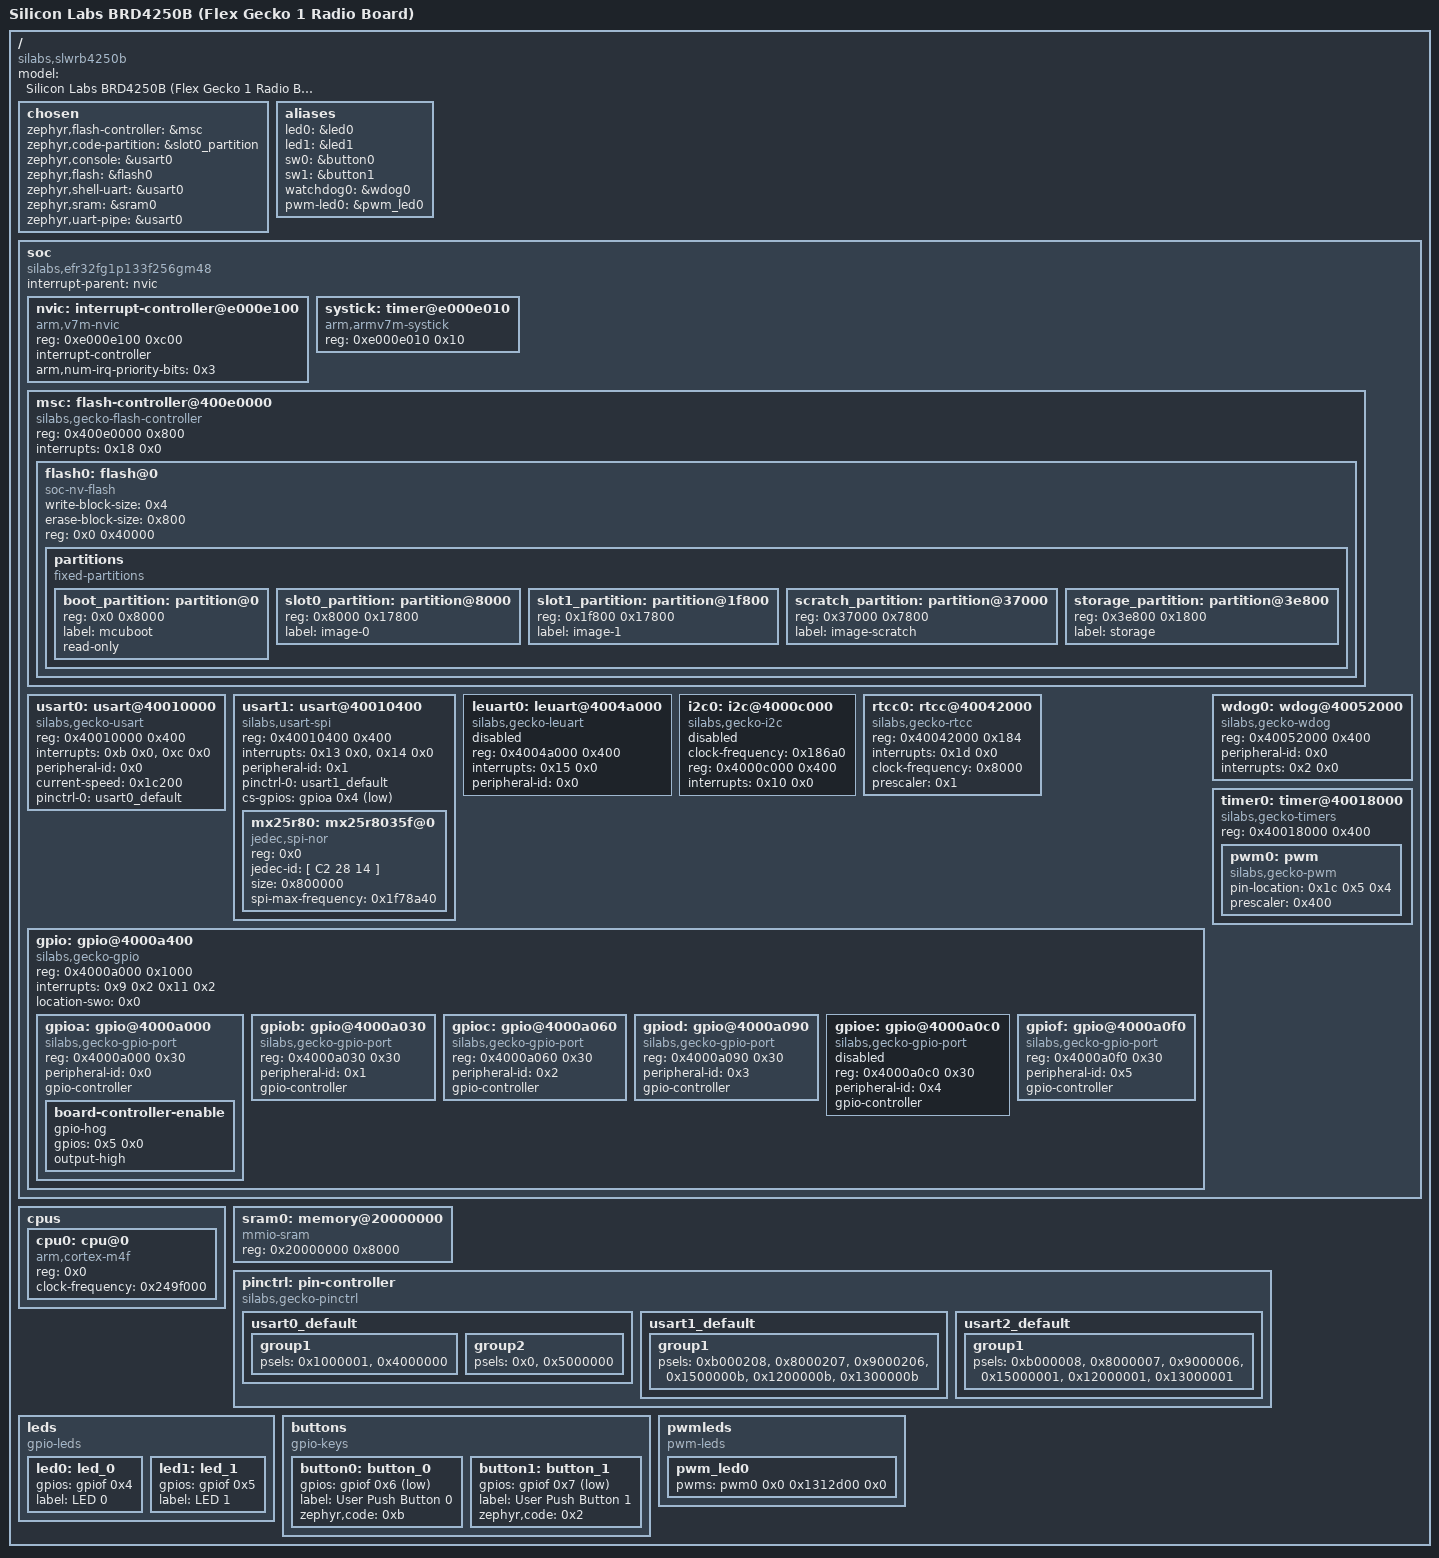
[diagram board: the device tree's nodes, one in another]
/dts-v1/;

/* node '/' defined in zephyr/dts/common/skeleton.dtsi:9 */
/ {
	#address-cells = < 0x1 >;                                   /* in zephyr/dts/common/skeleton.dtsi:10 */
	#size-cells = < 0x1 >;                                      /* in zephyr/dts/common/skeleton.dtsi:11 */
	model = "Silicon Labs BRD4250B (Flex Gecko 1 Radio Board)"; /* in zephyr/boards/silabs/radio_boards/slwrb4250b/slwrb4250b.dts:13 */
	compatible = "silabs,slwrb4250b",
	             "silabs,efr32fg1p";                            /* in zephyr/boards/silabs/radio_boards/slwrb4250b/slwrb4250b.dts:14 */

	/* node '/chosen' defined in zephyr/dts/common/skeleton.dtsi:13 */
	chosen {
		zephyr,flash-controller = &msc;           /* in zephyr/dts/arm/silabs/xg1/xg1.dtsi:10 */
		zephyr,code-partition = &slot0_partition; /* in zephyr/boards/silabs/radio_boards/common/efr32-series1-common.dtsi:12 */
		zephyr,console = &usart0;                 /* in zephyr/boards/silabs/radio_boards/common/efr32-series1-common.dtsi:13 */
		zephyr,flash = &flash0;                   /* in zephyr/boards/silabs/radio_boards/common/efr32-series1-common.dtsi:14 */
		zephyr,shell-uart = &usart0;              /* in zephyr/boards/silabs/radio_boards/common/efr32-series1-common.dtsi:15 */
		zephyr,sram = &sram0;                     /* in zephyr/boards/silabs/radio_boards/common/efr32-series1-common.dtsi:16 */
		zephyr,uart-pipe = &usart0;               /* in zephyr/boards/silabs/radio_boards/common/efr32-series1-common.dtsi:17 */
	};

	/* node '/aliases' defined in zephyr/dts/common/skeleton.dtsi:15 */
	aliases {
		led0 = &led0;         /* in zephyr/boards/silabs/radio_boards/common/efr32-series1-common.dtsi:22 */
		led1 = &led1;         /* in zephyr/boards/silabs/radio_boards/common/efr32-series1-common.dtsi:23 */
		sw0 = &button0;       /* in zephyr/boards/silabs/radio_boards/common/efr32-series1-common.dtsi:24 */
		sw1 = &button1;       /* in zephyr/boards/silabs/radio_boards/common/efr32-series1-common.dtsi:25 */
		watchdog0 = &wdog0;   /* in zephyr/boards/silabs/radio_boards/common/efr32-series1-common.dtsi:26 */
		pwm-led0 = &pwm_led0; /* in zephyr/boards/silabs/radio_boards/slwrb4250b/slwrb4250b.dts:17 */
	};

	/* node '/soc' defined in zephyr/dts/arm/armv7-m.dtsi:6 */
	soc {
		#address-cells = < 0x1 >;                   /* in zephyr/dts/arm/armv7-m.dtsi:7 */
		#size-cells = < 0x1 >;                      /* in zephyr/dts/arm/armv7-m.dtsi:8 */
		interrupt-parent = < &nvic >;               /* in zephyr/dts/arm/armv7-m.dtsi:10 */
		ranges;                                     /* in zephyr/dts/arm/armv7-m.dtsi:11 */
		compatible = "silabs,efr32fg1p133f256gm48",
		             "silabs,efr32fg1p",
		             "silabs,efr32",
		             "simple-bus";                  /* in zephyr/dts/arm/silabs/xg1/efr32fg1p133f256gm48.dtsi:12 */

		/* node '/soc/interrupt-controller@e000e100' defined in zephyr/dts/arm/armv7-m.dtsi:13 */
		nvic: interrupt-controller@e000e100 {
			#address-cells = < 0x1 >;            /* in zephyr/dts/arm/armv7-m.dtsi:14 */
			compatible = "arm,v7m-nvic";         /* in zephyr/dts/arm/armv7-m.dtsi:15 */
			reg = < 0xe000e100 0xc00 >;          /* in zephyr/dts/arm/armv7-m.dtsi:16 */
			interrupt-controller;                /* in zephyr/dts/arm/armv7-m.dtsi:17 */
			#interrupt-cells = < 0x2 >;          /* in zephyr/dts/arm/armv7-m.dtsi:18 */
			arm,num-irq-priority-bits = < 0x3 >; /* in zephyr/dts/arm/silabs/xg1/xg1.dtsi:184 */
			phandle = < 0x1 >;                   /* in zephyr/dts/arm/armv7-m.dtsi:10 */
		};

		/* node '/soc/timer@e000e010' defined in zephyr/dts/arm/armv7-m.dtsi:21 */
		systick: timer@e000e010 {
			compatible = "arm,armv7m-systick"; /* in zephyr/dts/arm/armv7-m.dtsi:22 */
			reg = < 0xe000e010 0x10 >;         /* in zephyr/dts/arm/armv7-m.dtsi:23 */
		};

		/* node '/soc/flash-controller@400e0000' defined in zephyr/dts/arm/silabs/xg1/xg1.dtsi:28 */
		msc: flash-controller@400e0000 {
			compatible = "silabs,gecko-flash-controller"; /* in zephyr/dts/arm/silabs/xg1/xg1.dtsi:29 */
			reg = < 0x400e0000 0x800 >;                   /* in zephyr/dts/arm/silabs/xg1/xg1.dtsi:30 */
			interrupts = < 0x18 0x0 >;                    /* in zephyr/dts/arm/silabs/xg1/xg1.dtsi:31 */
			#address-cells = < 0x1 >;                     /* in zephyr/dts/arm/silabs/xg1/xg1.dtsi:33 */
			#size-cells = < 0x1 >;                        /* in zephyr/dts/arm/silabs/xg1/xg1.dtsi:34 */

			/* node '/soc/flash-controller@400e0000/flash@0' defined in zephyr/dts/arm/silabs/xg1/xg1.dtsi:36 */
			flash0: flash@0 {
				compatible = "soc-nv-flash";  /* in zephyr/dts/arm/silabs/xg1/xg1.dtsi:37 */
				write-block-size = < 0x4 >;   /* in zephyr/dts/arm/silabs/xg1/xg1.dtsi:38 */
				erase-block-size = < 0x800 >; /* in zephyr/dts/arm/silabs/xg1/xg1.dtsi:39 */
				reg = < 0x0 0x40000 >;        /* in zephyr/dts/arm/silabs/xg1/efr32fg1p133f256gm48.dtsi:17 */

				/* node '/soc/flash-controller@400e0000/flash@0/partitions' defined in zephyr/boards/silabs/radio_boards/slwrb4250b/slwrb4250b.dts:44 */
				partitions {
					compatible = "fixed-partitions"; /* in zephyr/boards/silabs/radio_boards/slwrb4250b/slwrb4250b.dts:45 */
					#address-cells = < 0x1 >;        /* in zephyr/boards/silabs/radio_boards/slwrb4250b/slwrb4250b.dts:46 */
					#size-cells = < 0x1 >;           /* in zephyr/boards/silabs/radio_boards/slwrb4250b/slwrb4250b.dts:47 */

					/* node '/soc/flash-controller@400e0000/flash@0/partitions/partition@0' defined in zephyr/boards/silabs/radio_boards/slwrb4250b/slwrb4250b.dts:50 */
					boot_partition: partition@0 {
						reg = < 0x0 0x8000 >; /* in zephyr/boards/silabs/radio_boards/slwrb4250b/slwrb4250b.dts:51 */
						label = "mcuboot";    /* in zephyr/boards/silabs/radio_boards/slwrb4250b/slwrb4250b.dts:52 */
						read-only;            /* in zephyr/boards/silabs/radio_boards/slwrb4250b/slwrb4250b.dts:53 */
					};

					/* node '/soc/flash-controller@400e0000/flash@0/partitions/partition@8000' defined in zephyr/boards/silabs/radio_boards/slwrb4250b/slwrb4250b.dts:57 */
					slot0_partition: partition@8000 {
						reg = < 0x8000 0x17800 >; /* in zephyr/boards/silabs/radio_boards/slwrb4250b/slwrb4250b.dts:58 */
						label = "image-0";        /* in zephyr/boards/silabs/radio_boards/slwrb4250b/slwrb4250b.dts:59 */
					};

					/* node '/soc/flash-controller@400e0000/flash@0/partitions/partition@1f800' defined in zephyr/boards/silabs/radio_boards/slwrb4250b/slwrb4250b.dts:63 */
					slot1_partition: partition@1f800 {
						reg = < 0x1f800 0x17800 >; /* in zephyr/boards/silabs/radio_boards/slwrb4250b/slwrb4250b.dts:64 */
						label = "image-1";         /* in zephyr/boards/silabs/radio_boards/slwrb4250b/slwrb4250b.dts:65 */
					};

					/* node '/soc/flash-controller@400e0000/flash@0/partitions/partition@37000' defined in zephyr/boards/silabs/radio_boards/slwrb4250b/slwrb4250b.dts:69 */
					scratch_partition: partition@37000 {
						reg = < 0x37000 0x7800 >; /* in zephyr/boards/silabs/radio_boards/slwrb4250b/slwrb4250b.dts:70 */
						label = "image-scratch";  /* in zephyr/boards/silabs/radio_boards/slwrb4250b/slwrb4250b.dts:71 */
					};

					/* node '/soc/flash-controller@400e0000/flash@0/partitions/partition@3e800' defined in zephyr/boards/silabs/radio_boards/slwrb4250b/slwrb4250b.dts:75 */
					storage_partition: partition@3e800 {
						reg = < 0x3e800 0x1800 >; /* in zephyr/boards/silabs/radio_boards/slwrb4250b/slwrb4250b.dts:76 */
						label = "storage";        /* in zephyr/boards/silabs/radio_boards/slwrb4250b/slwrb4250b.dts:77 */
					};
				};
			};
		};

		/* node '/soc/usart@40010000' defined in zephyr/dts/arm/silabs/xg1/xg1.dtsi:43 */
		usart0: usart@40010000 {
			compatible = "silabs,gecko-usart"; /* in zephyr/dts/arm/silabs/xg1/xg1.dtsi:44 */
			reg = < 0x40010000 0x400 >;        /* in zephyr/dts/arm/silabs/xg1/xg1.dtsi:45 */
			interrupts = < 0xb 0x0 >,
			             < 0xc 0x0 >;          /* in zephyr/dts/arm/silabs/xg1/xg1.dtsi:46 */
			interrupt-names = "rx",
			                  "tx";            /* in zephyr/dts/arm/silabs/xg1/xg1.dtsi:47 */
			peripheral-id = < 0x0 >;           /* in zephyr/dts/arm/silabs/xg1/xg1.dtsi:48 */
			current-speed = < 0x1c200 >;       /* in zephyr/boards/silabs/radio_boards/slwrb4250b/slwrb4250b.dts:83 */
			pinctrl-0 = < &usart0_default >;   /* in zephyr/boards/silabs/radio_boards/slwrb4250b/slwrb4250b.dts:84 */
			pinctrl-names = "default";         /* in zephyr/boards/silabs/radio_boards/slwrb4250b/slwrb4250b.dts:85 */
			status = "okay";                   /* in zephyr/boards/silabs/radio_boards/slwrb4250b/slwrb4250b.dts:86 */
		};

		/* node '/soc/usart@40010400' defined in zephyr/dts/arm/silabs/xg1/xg1.dtsi:52 */
		usart1: usart@40010400 {
			reg = < 0x40010400 0x400 >;      /* in zephyr/dts/arm/silabs/xg1/xg1.dtsi:54 */
			interrupts = < 0x13 0x0 >,
			             < 0x14 0x0 >;       /* in zephyr/dts/arm/silabs/xg1/xg1.dtsi:55 */
			interrupt-names = "rx",
			                  "tx";          /* in zephyr/dts/arm/silabs/xg1/xg1.dtsi:56 */
			peripheral-id = < 0x1 >;         /* in zephyr/dts/arm/silabs/xg1/xg1.dtsi:57 */
			compatible = "silabs,usart-spi"; /* in zephyr/boards/silabs/radio_boards/common/efr32-series1-common.dtsi:70 */
			#address-cells = < 0x1 >;        /* in zephyr/boards/silabs/radio_boards/common/efr32-series1-common.dtsi:72 */
			#size-cells = < 0x0 >;           /* in zephyr/boards/silabs/radio_boards/common/efr32-series1-common.dtsi:73 */
			pinctrl-0 = < &usart1_default >; /* in zephyr/boards/silabs/radio_boards/common/efr32-series1-common.dtsi:75 */
			pinctrl-names = "default";       /* in zephyr/boards/silabs/radio_boards/common/efr32-series1-common.dtsi:76 */
			cs-gpios = < &gpioa 0x4 0x1 >;   /* in zephyr/boards/silabs/radio_boards/common/efr32-series1-common.dtsi:78 */
			status = "okay";                 /* in zephyr/boards/silabs/radio_boards/common/efr32-series1-common.dtsi:80 */

			/* node '/soc/usart@40010400/mx25r8035f@0' defined in zephyr/boards/silabs/radio_boards/common/efr32-series1-common.dtsi:82 */
			mx25r80: mx25r8035f@0 {
				compatible = "jedec,spi-nor";      /* in zephyr/boards/silabs/radio_boards/common/efr32-series1-common.dtsi:83 */
				reg = < 0x0 >;                     /* in zephyr/boards/silabs/radio_boards/common/efr32-series1-common.dtsi:84 */
				jedec-id = [ C2 28 14 ];           /* in zephyr/boards/silabs/radio_boards/common/efr32-series1-common.dtsi:85 */
				size = < 0x800000 >;               /* in zephyr/boards/silabs/radio_boards/common/efr32-series1-common.dtsi:86 */
				spi-max-frequency = < 0x1f78a40 >; /* in zephyr/boards/silabs/radio_boards/common/efr32-series1-common.dtsi:87 */
			};
		};

		/* node '/soc/leuart@4004a000' defined in zephyr/dts/arm/silabs/xg1/xg1.dtsi:61 */
		leuart0: leuart@4004a000 {
			compatible = "silabs,gecko-leuart"; /* in zephyr/dts/arm/silabs/xg1/xg1.dtsi:62 */
			reg = < 0x4004a000 0x400 >;         /* in zephyr/dts/arm/silabs/xg1/xg1.dtsi:63 */
			interrupts = < 0x15 0x0 >;          /* in zephyr/dts/arm/silabs/xg1/xg1.dtsi:64 */
			peripheral-id = < 0x0 >;            /* in zephyr/dts/arm/silabs/xg1/xg1.dtsi:65 */
			status = "disabled";                /* in zephyr/dts/arm/silabs/xg1/xg1.dtsi:66 */
		};

		/* node '/soc/i2c@4000c000' defined in zephyr/dts/arm/silabs/xg1/xg1.dtsi:69 */
		i2c0: i2c@4000c000 {
			compatible = "silabs,gecko-i2c"; /* in zephyr/dts/arm/silabs/xg1/xg1.dtsi:70 */
			clock-frequency = < 0x186a0 >;   /* in zephyr/dts/arm/silabs/xg1/xg1.dtsi:71 */
			#address-cells = < 0x1 >;        /* in zephyr/dts/arm/silabs/xg1/xg1.dtsi:72 */
			#size-cells = < 0x0 >;           /* in zephyr/dts/arm/silabs/xg1/xg1.dtsi:73 */
			reg = < 0x4000c000 0x400 >;      /* in zephyr/dts/arm/silabs/xg1/xg1.dtsi:74 */
			interrupts = < 0x10 0x0 >;       /* in zephyr/dts/arm/silabs/xg1/xg1.dtsi:75 */
			status = "disabled";             /* in zephyr/dts/arm/silabs/xg1/xg1.dtsi:76 */
		};

		/* node '/soc/rtcc@40042000' defined in zephyr/dts/arm/silabs/xg1/xg1.dtsi:79 */
		rtcc0: rtcc@40042000 {
			compatible = "silabs,gecko-rtcc"; /* in zephyr/dts/arm/silabs/xg1/xg1.dtsi:80 */
			reg = < 0x40042000 0x184 >;       /* in zephyr/dts/arm/silabs/xg1/xg1.dtsi:81 */
			interrupts = < 0x1d 0x0 >;        /* in zephyr/dts/arm/silabs/xg1/xg1.dtsi:82 */
			clock-frequency = < 0x8000 >;     /* in zephyr/dts/arm/silabs/xg1/xg1.dtsi:83 */
			prescaler = < 0x1 >;              /* in zephyr/boards/silabs/radio_boards/common/efr32-series1-common.dtsi:92 */
			status = "okay";                  /* in zephyr/boards/silabs/radio_boards/common/efr32-series1-common.dtsi:93 */
		};

		/* node '/soc/gpio@4000a400' defined in zephyr/dts/arm/silabs/xg1/xg1.dtsi:88 */
		gpio: gpio@4000a400 {
			compatible = "silabs,gecko-gpio";  /* in zephyr/dts/arm/silabs/xg1/xg1.dtsi:89 */
			reg = < 0x4000a000 0x1000 >;       /* in zephyr/dts/arm/silabs/xg1/xg1.dtsi:90 */
			interrupts = < 0x9 0x2 0x11 0x2 >; /* in zephyr/dts/arm/silabs/xg1/xg1.dtsi:91 */
			interrupt-names = "GPIO_EVEN",
			                  "GPIO_ODD";      /* in zephyr/dts/arm/silabs/xg1/xg1.dtsi:92 */
			ranges;                            /* in zephyr/dts/arm/silabs/xg1/xg1.dtsi:94 */
			#address-cells = < 0x1 >;          /* in zephyr/dts/arm/silabs/xg1/xg1.dtsi:95 */
			#size-cells = < 0x1 >;             /* in zephyr/dts/arm/silabs/xg1/xg1.dtsi:96 */
			location-swo = < 0x0 >;            /* in zephyr/boards/silabs/radio_boards/common/efr32-series1-common.dtsi:97 */
			status = "okay";                   /* in zephyr/boards/silabs/radio_boards/common/efr32-series1-common.dtsi:98 */

			/* node '/soc/gpio@4000a400/gpio@4000a000' defined in zephyr/dts/arm/silabs/xg1/xg1.dtsi:98 */
			gpioa: gpio@4000a000 {
				compatible = "silabs,gecko-gpio-port"; /* in zephyr/dts/arm/silabs/xg1/xg1.dtsi:99 */
				reg = < 0x4000a000 0x30 >;             /* in zephyr/dts/arm/silabs/xg1/xg1.dtsi:100 */
				peripheral-id = < 0x0 >;               /* in zephyr/dts/arm/silabs/xg1/xg1.dtsi:101 */
				gpio-controller;                       /* in zephyr/dts/arm/silabs/xg1/xg1.dtsi:102 */
				#gpio-cells = < 0x2 >;                 /* in zephyr/dts/arm/silabs/xg1/xg1.dtsi:103 */
				status = "okay";                       /* in zephyr/boards/silabs/radio_boards/common/efr32-series1-common.dtsi:102 */
				phandle = < 0x4 >;                     /* in zephyr/boards/silabs/radio_boards/common/efr32-series1-common.dtsi:78 */

				/* node '/soc/gpio@4000a400/gpio@4000a000/board-controller-enable' defined in zephyr/boards/silabs/radio_boards/common/efr32-series1-common.dtsi:104 */
				board-controller-enable {
					gpio-hog;            /* in zephyr/boards/silabs/radio_boards/common/efr32-series1-common.dtsi:105 */
					gpios = < 0x5 0x0 >; /* in zephyr/boards/silabs/radio_boards/common/efr32-series1-common.dtsi:106 */
					output-high;         /* in zephyr/boards/silabs/radio_boards/common/efr32-series1-common.dtsi:107 */
				};
			};

			/* node '/soc/gpio@4000a400/gpio@4000a030' defined in zephyr/dts/arm/silabs/xg1/xg1.dtsi:107 */
			gpiob: gpio@4000a030 {
				compatible = "silabs,gecko-gpio-port"; /* in zephyr/dts/arm/silabs/xg1/xg1.dtsi:108 */
				reg = < 0x4000a030 0x30 >;             /* in zephyr/dts/arm/silabs/xg1/xg1.dtsi:109 */
				peripheral-id = < 0x1 >;               /* in zephyr/dts/arm/silabs/xg1/xg1.dtsi:110 */
				gpio-controller;                       /* in zephyr/dts/arm/silabs/xg1/xg1.dtsi:111 */
				#gpio-cells = < 0x2 >;                 /* in zephyr/dts/arm/silabs/xg1/xg1.dtsi:112 */
				status = "okay";                       /* in zephyr/boards/silabs/radio_boards/common/efr32-series1-common.dtsi:112 */
			};

			/* node '/soc/gpio@4000a400/gpio@4000a060' defined in zephyr/dts/arm/silabs/xg1/xg1.dtsi:116 */
			gpioc: gpio@4000a060 {
				compatible = "silabs,gecko-gpio-port"; /* in zephyr/dts/arm/silabs/xg1/xg1.dtsi:117 */
				reg = < 0x4000a060 0x30 >;             /* in zephyr/dts/arm/silabs/xg1/xg1.dtsi:118 */
				peripheral-id = < 0x2 >;               /* in zephyr/dts/arm/silabs/xg1/xg1.dtsi:119 */
				gpio-controller;                       /* in zephyr/dts/arm/silabs/xg1/xg1.dtsi:120 */
				#gpio-cells = < 0x2 >;                 /* in zephyr/dts/arm/silabs/xg1/xg1.dtsi:121 */
				status = "okay";                       /* in zephyr/boards/silabs/radio_boards/common/efr32-series1-common.dtsi:116 */
			};

			/* node '/soc/gpio@4000a400/gpio@4000a090' defined in zephyr/dts/arm/silabs/xg1/xg1.dtsi:125 */
			gpiod: gpio@4000a090 {
				compatible = "silabs,gecko-gpio-port"; /* in zephyr/dts/arm/silabs/xg1/xg1.dtsi:126 */
				reg = < 0x4000a090 0x30 >;             /* in zephyr/dts/arm/silabs/xg1/xg1.dtsi:127 */
				peripheral-id = < 0x3 >;               /* in zephyr/dts/arm/silabs/xg1/xg1.dtsi:128 */
				gpio-controller;                       /* in zephyr/dts/arm/silabs/xg1/xg1.dtsi:129 */
				#gpio-cells = < 0x2 >;                 /* in zephyr/dts/arm/silabs/xg1/xg1.dtsi:130 */
				status = "okay";                       /* in zephyr/boards/silabs/radio_boards/common/efr32-series1-common.dtsi:120 */
			};

			/* node '/soc/gpio@4000a400/gpio@4000a0c0' defined in zephyr/dts/arm/silabs/xg1/xg1.dtsi:134 */
			gpioe: gpio@4000a0c0 {
				compatible = "silabs,gecko-gpio-port"; /* in zephyr/dts/arm/silabs/xg1/xg1.dtsi:135 */
				reg = < 0x4000a0c0 0x30 >;             /* in zephyr/dts/arm/silabs/xg1/xg1.dtsi:136 */
				peripheral-id = < 0x4 >;               /* in zephyr/dts/arm/silabs/xg1/xg1.dtsi:137 */
				gpio-controller;                       /* in zephyr/dts/arm/silabs/xg1/xg1.dtsi:138 */
				#gpio-cells = < 0x2 >;                 /* in zephyr/dts/arm/silabs/xg1/xg1.dtsi:139 */
				status = "disabled";                   /* in zephyr/dts/arm/silabs/xg1/xg1.dtsi:140 */
			};

			/* node '/soc/gpio@4000a400/gpio@4000a0f0' defined in zephyr/dts/arm/silabs/xg1/xg1.dtsi:143 */
			gpiof: gpio@4000a0f0 {
				compatible = "silabs,gecko-gpio-port"; /* in zephyr/dts/arm/silabs/xg1/xg1.dtsi:144 */
				reg = < 0x4000a0f0 0x30 >;             /* in zephyr/dts/arm/silabs/xg1/xg1.dtsi:145 */
				peripheral-id = < 0x5 >;               /* in zephyr/dts/arm/silabs/xg1/xg1.dtsi:146 */
				gpio-controller;                       /* in zephyr/dts/arm/silabs/xg1/xg1.dtsi:147 */
				#gpio-cells = < 0x2 >;                 /* in zephyr/dts/arm/silabs/xg1/xg1.dtsi:148 */
				status = "okay";                       /* in zephyr/boards/silabs/radio_boards/common/efr32-series1-common.dtsi:124 */
				phandle = < 0x5 >;                     /* in zephyr/boards/silabs/radio_boards/common/efr32-series1-common.dtsi:33 */
			};
		};

		/* node '/soc/wdog@40052000' defined in zephyr/dts/arm/silabs/xg1/xg1.dtsi:153 */
		wdog0: wdog@40052000 {
			compatible = "silabs,gecko-wdog"; /* in zephyr/dts/arm/silabs/xg1/xg1.dtsi:154 */
			reg = < 0x40052000 0x400 >;       /* in zephyr/dts/arm/silabs/xg1/xg1.dtsi:155 */
			peripheral-id = < 0x0 >;          /* in zephyr/dts/arm/silabs/xg1/xg1.dtsi:156 */
			interrupts = < 0x2 0x0 >;         /* in zephyr/dts/arm/silabs/xg1/xg1.dtsi:157 */
			status = "okay";                  /* in zephyr/boards/silabs/radio_boards/common/efr32-series1-common.dtsi:128 */
		};

		/* node '/soc/timer@40018000' defined in zephyr/dts/arm/silabs/xg1/xg1.dtsi:161 */
		timer0: timer@40018000 {
			compatible = "silabs,gecko-timers"; /* in zephyr/dts/arm/silabs/xg1/xg1.dtsi:162 */
			reg = < 0x40018000 0x400 >;         /* in zephyr/dts/arm/silabs/xg1/xg1.dtsi:163 */
			status = "okay";                    /* in zephyr/boards/silabs/radio_boards/slwrb4250b/slwrb4250b.dts:34 */

			/* node '/soc/timer@40018000/pwm' defined in zephyr/dts/arm/silabs/xg1/xg1.dtsi:166 */
			pwm0: pwm {
				compatible = "silabs,gecko-pwm"; /* in zephyr/dts/arm/silabs/xg1/xg1.dtsi:167 */
				#pwm-cells = < 0x3 >;            /* in zephyr/dts/arm/silabs/xg1/xg1.dtsi:169 */
				pin-location = < 0x1c 0x5 0x4 >; /* in zephyr/boards/silabs/radio_boards/slwrb4250b/slwrb4250b.dts:37 */
				prescaler = < 0x400 >;           /* in zephyr/boards/silabs/radio_boards/slwrb4250b/slwrb4250b.dts:38 */
				status = "okay";                 /* in zephyr/boards/silabs/radio_boards/slwrb4250b/slwrb4250b.dts:39 */
				phandle = < 0x6 >;               /* in zephyr/boards/silabs/radio_boards/slwrb4250b/slwrb4250b.dts:24 */
			};
		};
	};

	/* node '/cpus' defined in zephyr/dts/arm/silabs/xg1/xg1.dtsi:13 */
	cpus {
		#address-cells = < 0x1 >; /* in zephyr/dts/arm/silabs/xg1/xg1.dtsi:14 */
		#size-cells = < 0x0 >;    /* in zephyr/dts/arm/silabs/xg1/xg1.dtsi:15 */

		/* node '/cpus/cpu@0' defined in zephyr/dts/arm/silabs/xg1/xg1.dtsi:17 */
		cpu0: cpu@0 {
			compatible = "arm,cortex-m4f";   /* in zephyr/dts/arm/silabs/xg1/xg1.dtsi:18 */
			reg = < 0x0 >;                   /* in zephyr/dts/arm/silabs/xg1/xg1.dtsi:19 */
			clock-frequency = < 0x249f000 >; /* in zephyr/boards/silabs/radio_boards/slwrb4250b/slwrb4250b.dts:30 */
		};
	};

	/* node '/memory@20000000' defined in zephyr/dts/arm/silabs/xg1/xg1.dtsi:23 */
	sram0: memory@20000000 {
		compatible = "mmio-sram";    /* in zephyr/dts/arm/silabs/xg1/xg1.dtsi:24 */
		reg = < 0x20000000 0x8000 >; /* in zephyr/dts/arm/silabs/xg1/efr32fg1p133f256gm48.dtsi:21 */
	};

	/* node '/pin-controller' defined in zephyr/dts/arm/silabs/xg1/xg1.dtsi:174 */
	pinctrl: pin-controller {
		compatible = "silabs,gecko-pinctrl"; /* in zephyr/dts/arm/silabs/xg1/xg1.dtsi:179 */

		/* node '/pin-controller/usart0_default' defined in zephyr/boards/silabs/radio_boards/common/efr32-series1-common-pinctrl.dtsi:11 */
		usart0_default: usart0_default {
			phandle = < 0x2 >; /* in zephyr/boards/silabs/radio_boards/slwrb4250b/slwrb4250b.dts:84 */

			/* node '/pin-controller/usart0_default/group1' defined in zephyr/boards/silabs/radio_boards/common/efr32-series1-common-pinctrl.dtsi:12 */
			group1 {
				psels = < 0x1000001 >,
				        < 0x4000000 >; /* in zephyr/boards/silabs/radio_boards/slwrb4250b/slwrb4250b-pinctrl.dtsi:14 */
			};

			/* node '/pin-controller/usart0_default/group2' defined in zephyr/boards/silabs/radio_boards/slwrb4250b/slwrb4250b-pinctrl.dtsi:18 */
			group2 {
				psels = < 0x0 >,
				        < 0x5000000 >; /* in zephyr/boards/silabs/radio_boards/slwrb4250b/slwrb4250b-pinctrl.dtsi:20 */
			};
		};

		/* node '/pin-controller/usart1_default' defined in zephyr/boards/silabs/radio_boards/common/efr32-series1-common-pinctrl.dtsi:20 */
		usart1_default: usart1_default {
			phandle = < 0x3 >; /* in zephyr/boards/silabs/radio_boards/common/efr32-series1-common.dtsi:75 */

			/* node '/pin-controller/usart1_default/group1' defined in zephyr/boards/silabs/radio_boards/common/efr32-series1-common-pinctrl.dtsi:21 */
			group1 {
				psels = < 0xb000208 >,
				        < 0x8000207 >,
				        < 0x9000206 >,
				        < 0x1500000b >,
				        < 0x1200000b >,
				        < 0x1300000b >; /* in zephyr/boards/silabs/radio_boards/common/efr32-series1-common-pinctrl.dtsi:22 */
			};
		};

		/* node '/pin-controller/usart2_default' defined in zephyr/boards/silabs/radio_boards/common/efr32-series1-common-pinctrl.dtsi:31 */
		usart2_default: usart2_default {

			/* node '/pin-controller/usart2_default/group1' defined in zephyr/boards/silabs/radio_boards/common/efr32-series1-common-pinctrl.dtsi:32 */
			group1 {
				psels = < 0xb000008 >,
				        < 0x8000007 >,
				        < 0x9000006 >,
				        < 0x15000001 >,
				        < 0x12000001 >,
				        < 0x13000001 >; /* in zephyr/boards/silabs/radio_boards/common/efr32-series1-common-pinctrl.dtsi:33 */
			};
		};
	};

	/* node '/leds' defined in zephyr/boards/silabs/radio_boards/common/efr32-series1-common.dtsi:29 */
	leds {
		compatible = "gpio-leds"; /* in zephyr/boards/silabs/radio_boards/common/efr32-series1-common.dtsi:30 */

		/* node '/leds/led_0' defined in zephyr/boards/silabs/radio_boards/common/efr32-series1-common.dtsi:32 */
		led0: led_0 {
			gpios = < &gpiof 0x4 0x0 >; /* in zephyr/boards/silabs/radio_boards/common/efr32-series1-common.dtsi:33 */
			label = "LED 0";            /* in zephyr/boards/silabs/radio_boards/common/efr32-series1-common.dtsi:34 */
		};

		/* node '/leds/led_1' defined in zephyr/boards/silabs/radio_boards/common/efr32-series1-common.dtsi:37 */
		led1: led_1 {
			gpios = < &gpiof 0x5 0x0 >; /* in zephyr/boards/silabs/radio_boards/common/efr32-series1-common.dtsi:38 */
			label = "LED 1";            /* in zephyr/boards/silabs/radio_boards/common/efr32-series1-common.dtsi:39 */
		};
	};

	/* node '/buttons' defined in zephyr/boards/silabs/radio_boards/common/efr32-series1-common.dtsi:43 */
	buttons {
		compatible = "gpio-keys"; /* in zephyr/boards/silabs/radio_boards/common/efr32-series1-common.dtsi:44 */

		/* node '/buttons/button_0' defined in zephyr/boards/silabs/radio_boards/common/efr32-series1-common.dtsi:46 */
		button0: button_0 {
			gpios = < &gpiof 0x6 0x1 >;   /* in zephyr/boards/silabs/radio_boards/common/efr32-series1-common.dtsi:48 */
			label = "User Push Button 0"; /* in zephyr/boards/silabs/radio_boards/common/efr32-series1-common.dtsi:49 */
			zephyr,code = < 0xb >;        /* in zephyr/boards/silabs/radio_boards/common/efr32-series1-common.dtsi:50 */
		};

		/* node '/buttons/button_1' defined in zephyr/boards/silabs/radio_boards/common/efr32-series1-common.dtsi:53 */
		button1: button_1 {
			gpios = < &gpiof 0x7 0x1 >;   /* in zephyr/boards/silabs/radio_boards/common/efr32-series1-common.dtsi:55 */
			label = "User Push Button 1"; /* in zephyr/boards/silabs/radio_boards/common/efr32-series1-common.dtsi:56 */
			zephyr,code = < 0x2 >;        /* in zephyr/boards/silabs/radio_boards/common/efr32-series1-common.dtsi:57 */
		};
	};

	/* node '/pwmleds' defined in zephyr/boards/silabs/radio_boards/slwrb4250b/slwrb4250b.dts:20 */
	pwmleds {
		compatible = "pwm-leds"; /* in zephyr/boards/silabs/radio_boards/slwrb4250b/slwrb4250b.dts:21 */

		/* node '/pwmleds/pwm_led0' defined in zephyr/boards/silabs/radio_boards/slwrb4250b/slwrb4250b.dts:23 */
		pwm_led0: pwm_led0 {
			pwms = < &pwm0 0x0 0x1312d00 0x0 >; /* in zephyr/boards/silabs/radio_boards/slwrb4250b/slwrb4250b.dts:24 */
		};
	};
};
